# mc200 register map
Registers are 32-bit, access not given, no defined reset value unless marked. A register's access mark holds for its fields unless they carry their own. Addresses are absolute; registers are grouped by the start of their names; [hi:lo] are bit positions; {n}, {i} and the like mark numbered series.

## PMU
0x480A0000 PMU_PWR_MODE
  [1:0] PWR_MODE
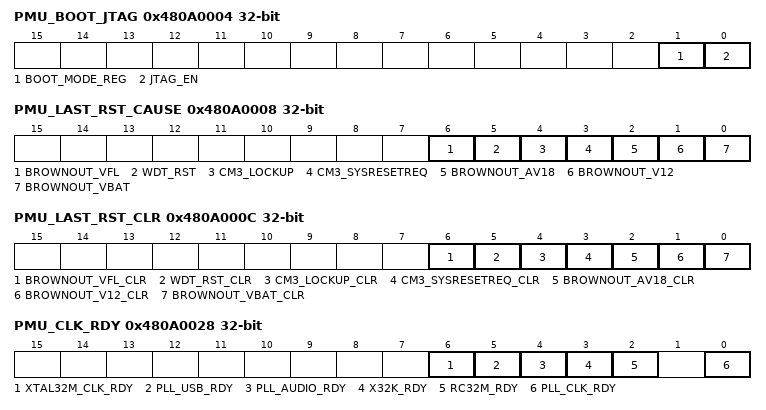
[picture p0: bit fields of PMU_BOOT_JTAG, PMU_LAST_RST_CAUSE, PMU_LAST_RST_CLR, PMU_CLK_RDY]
0x480A0004 PMU_BOOT_JTAG
  [1] BOOT_MODE_REG, [0] JTAG_EN
0x480A0008 PMU_LAST_RST_CAUSE
  [6] BROWNOUT_VFL, [5] WDT_RST, [4] CM3_LOCKUP, [3] CM3_SYSRESETREQ, [2] BROWNOUT_AV18, [1] BROWNOUT_V12, [0] BROWNOUT_VBAT
0x480A000C PMU_LAST_RST_CLR
  [6] BROWNOUT_VFL_CLR, [5] WDT_RST_CLR, [4] CM3_LOCKUP_CLR, [3] CM3_SYSRESETREQ_CLR, [2] BROWNOUT_AV18_CLR, [1] BROWNOUT_V12_CLR, [0] BROWNOUT_VBAT_CLR
0x480A0010 PMU_WAKE_SRC_CLR
  [0] CLR_PIN_INT
0x480A0018 PMU_CLK_SRC
  [1:0] SYS_CLK_SEL
0x480A0020 PMU_CLK_DIV
  [5:0] DIV_RATIO
0x480A0024 PMU_VFL_CTRL
  [0] VFL_CTRL
0x480A0028 PMU_CLK_RDY
  [6] XTAL32M_CLK_RDY, [5] PLL_USB_RDY, [4] PLL_AUDIO_RDY, [3] X32K_RDY, [2] RC32M_RDY, [0] PLL_CLK_RDY
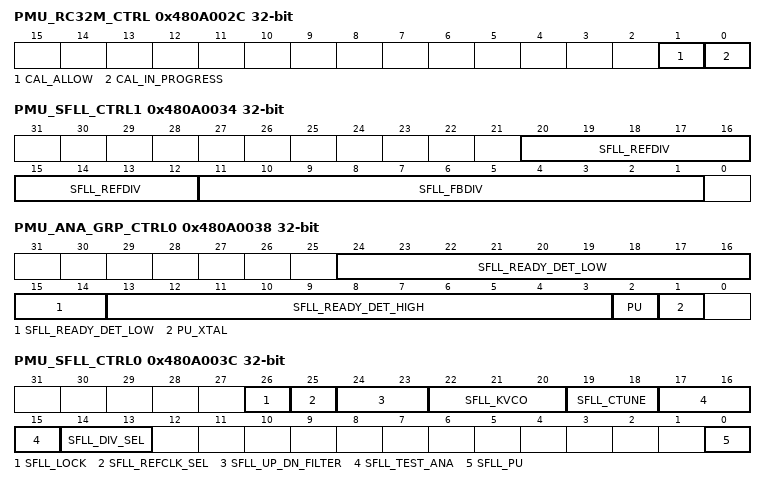
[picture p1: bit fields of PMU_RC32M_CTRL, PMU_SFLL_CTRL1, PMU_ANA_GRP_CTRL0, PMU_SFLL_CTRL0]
0x480A002C PMU_RC32M_CTRL
  [1] CAL_ALLOW, [0] CAL_IN_PROGRESS
0x480A0034 PMU_SFLL_CTRL1
  [20:12] SFLL_REFDIV, [11:1] SFLL_FBDIV
0x480A0038 PMU_ANA_GRP_CTRL0
  [24:14] SFLL_READY_DET_LOW, [13:3] SFLL_READY_DET_HIGH, [2] PU, [1] PU_XTAL
0x480A003C PMU_SFLL_CTRL0
  [26] SFLL_LOCK, [25] SFLL_REFCLK_SEL, [24:23] SFLL_UP_DN_FILTER, [22:20] SFLL_KVCO, [19:18] SFLL_CTUNE, [17:15] SFLL_TEST_ANA, [14:13] SFLL_DIV_SEL, [0] SFLL_PU
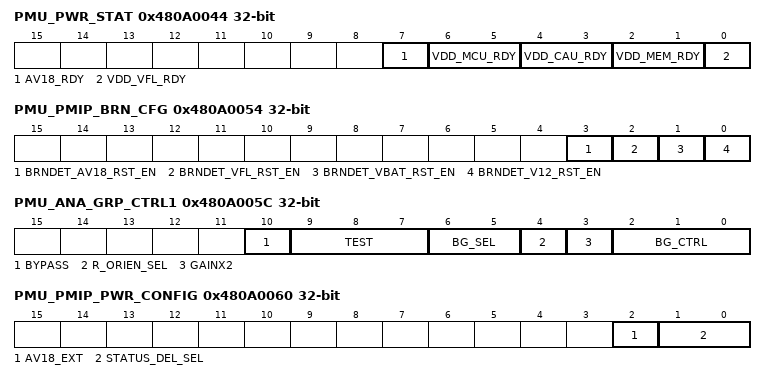
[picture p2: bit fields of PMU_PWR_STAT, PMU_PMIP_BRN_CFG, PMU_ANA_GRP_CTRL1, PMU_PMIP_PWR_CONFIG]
0x480A0044 PMU_PWR_STAT
  [7] AV18_RDY, [6:5] VDD_MCU_RDY, [4:3] VDD_CAU_RDY, [2:1] VDD_MEM_RDY, [0] VDD_VFL_RDY
0x480A0054 PMU_PMIP_BRN_CFG
  [3] BRNDET_AV18_RST_EN, [2] BRNDET_VFL_RST_EN, [1] BRNDET_VBAT_RST_EN, [0] BRNDET_V12_RST_EN
0x480A005C PMU_ANA_GRP_CTRL1
  [10] BYPASS, [9:7] TEST, [6:5] BG_SEL, [4] R_ORIEN_SEL, [3] GAINX2, [2:0] BG_CTRL
0x480A0060 PMU_PMIP_PWR_CONFIG
  [2] AV18_EXT, [1:0] STATUS_DEL_SEL
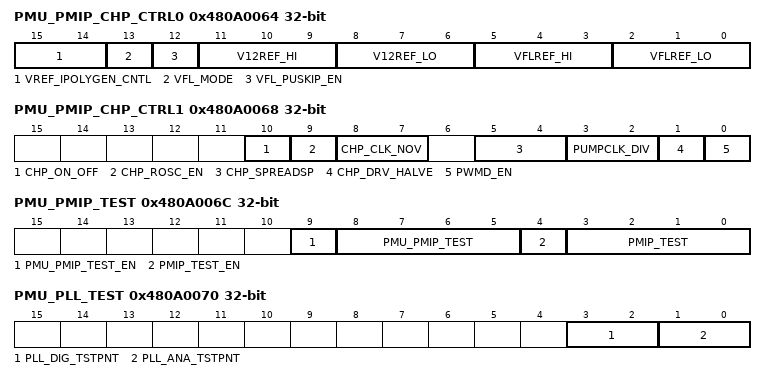
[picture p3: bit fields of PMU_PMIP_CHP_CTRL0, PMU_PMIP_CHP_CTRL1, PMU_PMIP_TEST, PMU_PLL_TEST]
0x480A0064 PMU_PMIP_CHP_CTRL0
  [15:14] VREF_IPOLYGEN_CNTL, [13] VFL_MODE, [12] VFL_PUSKIP_EN, [11:9] V12REF_HI, [8:6] V12REF_LO, [5:3] VFLREF_HI, [2:0] VFLREF_LO
0x480A0068 PMU_PMIP_CHP_CTRL1
  [10] CHP_ON_OFF, [9] CHP_ROSC_EN, [8:7] CHP_CLK_NOV, [5:4] CHP_SPREADSP, [3:2] PUMPCLK_DIV, [1] CHP_DRV_HALVE, [0] PWMD_EN
0x480A006C PMU_PMIP_TEST
  [9] PMU_PMIP_TEST_EN, [8:5] PMU_PMIP_TEST, [4] PMIP_TEST_EN, [3:0] PMIP_TEST
0x480A0070 PMU_PLL_TEST
  [3:2] PLL_DIG_TSTPNT, [1:0] PLL_ANA_TSTPNT
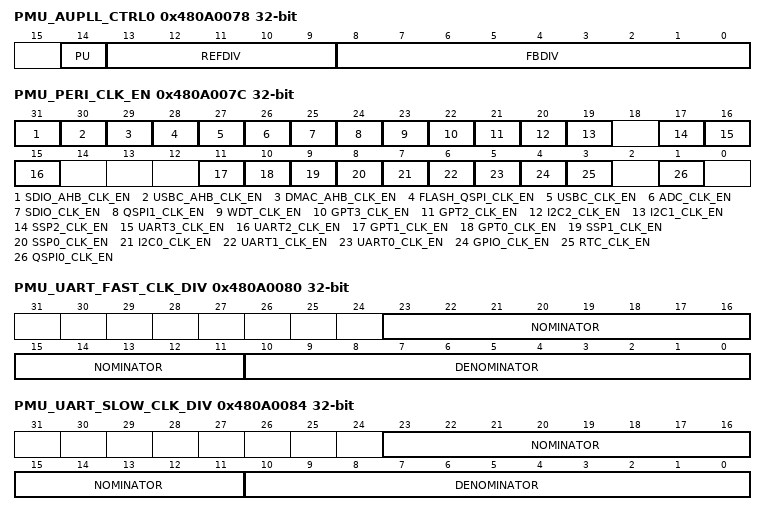
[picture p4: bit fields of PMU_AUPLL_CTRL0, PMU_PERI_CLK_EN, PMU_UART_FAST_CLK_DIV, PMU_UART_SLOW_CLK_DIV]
0x480A0078 PMU_AUPLL_CTRL0
  [14] PU, [13:9] REFDIV, [8:0] FBDIV
0x480A007C PMU_PERI_CLK_EN
  [31] SDIO_AHB_CLK_EN, [30] USBC_AHB_CLK_EN, [29] DMAC_AHB_CLK_EN, [28] FLASH_QSPI_CLK_EN, [27] USBC_CLK_EN, [26] ADC_CLK_EN, [25] SDIO_CLK_EN, [24] QSPI1_CLK_EN, [23] WDT_CLK_EN, [22] GPT3_CLK_EN, [21] GPT2_CLK_EN, [20] I2C2_CLK_EN, [19] I2C1_CLK_EN, [17] SSP2_CLK_EN, [16] UART3_CLK_EN, [15] UART2_CLK_EN, [11] GPT1_CLK_EN, [10] GPT0_CLK_EN, [9] SSP1_CLK_EN, [8] SSP0_CLK_EN, [7] I2C0_CLK_EN, [6] UART1_CLK_EN, [5] UART0_CLK_EN, [4] GPIO_CLK_EN, [3] RTC_CLK_EN, [1] QSPI0_CLK_EN
0x480A0080 PMU_UART_FAST_CLK_DIV
  [23:11] NOMINATOR, [10:0] DENOMINATOR
0x480A0084 PMU_UART_SLOW_CLK_DIV
  [23:11] NOMINATOR, [10:0] DENOMINATOR
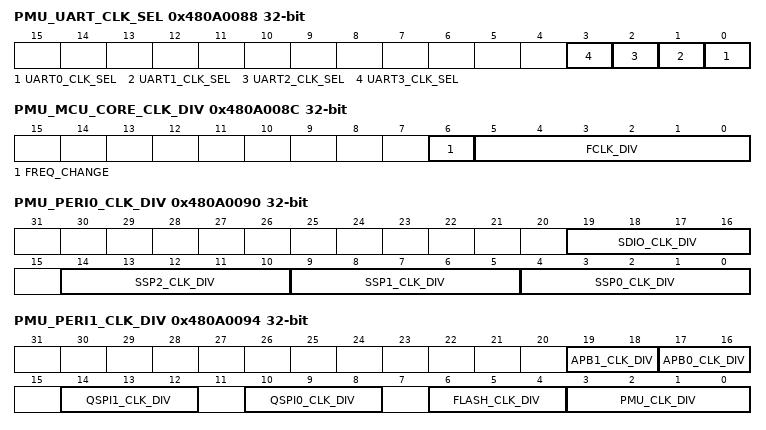
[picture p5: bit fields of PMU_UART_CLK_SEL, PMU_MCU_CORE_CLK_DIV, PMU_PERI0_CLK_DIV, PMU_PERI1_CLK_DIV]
0x480A0088 PMU_UART_CLK_SEL
  [n] UART{n}_CLK_SEL (n=0..3)
0x480A008C PMU_MCU_CORE_CLK_DIV
  [6] FREQ_CHANGE, [5:0] FCLK_DIV
0x480A0090 PMU_PERI0_CLK_DIV
  [19:16] SDIO_CLK_DIV, [14:10] SSP2_CLK_DIV, [9:5] SSP1_CLK_DIV, [4:0] SSP0_CLK_DIV
0x480A0094 PMU_PERI1_CLK_DIV
  [19:18] APB1_CLK_DIV, [17:16] APB0_CLK_DIV, [14:12] QSPI1_CLK_DIV, [10:8] QSPI0_CLK_DIV, [6:4] FLASH_CLK_DIV, [3:0] PMU_CLK_DIV
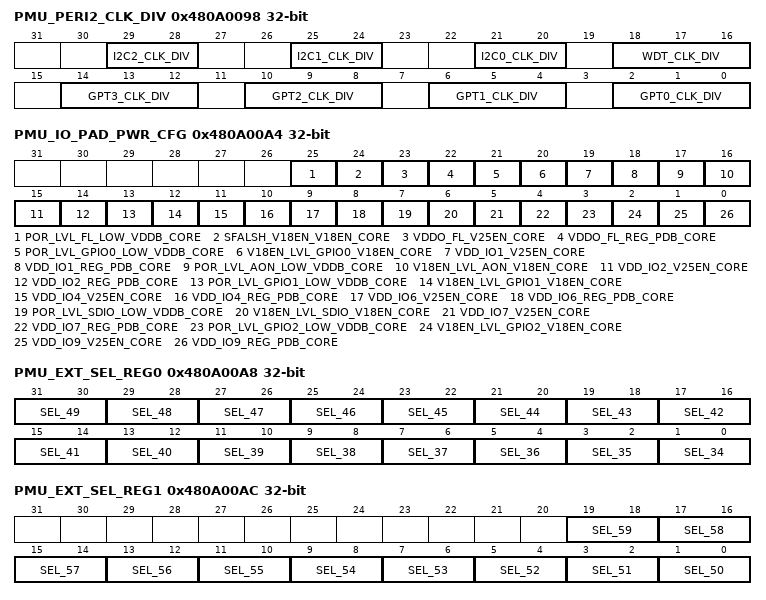
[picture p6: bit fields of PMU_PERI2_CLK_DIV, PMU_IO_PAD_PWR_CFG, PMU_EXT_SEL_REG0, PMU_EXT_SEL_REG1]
0x480A0098 PMU_PERI2_CLK_DIV
  [29:28] I2C2_CLK_DIV, [25:24] I2C1_CLK_DIV, [21:20] I2C0_CLK_DIV, [18:16] WDT_CLK_DIV, [4n+2:4n] GPT{n}_CLK_DIV (n=0..3)
0x480A009C PMU_CAU_CLK_SEL
  [1:0] CAU_CLK_SEL
0x480A00A4 PMU_IO_PAD_PWR_CFG
  [25] POR_LVL_FL_LOW_VDDB_CORE, [24] SFALSH_V18EN_V18EN_CORE, [23] VDDO_FL_V25EN_CORE, [22] VDDO_FL_REG_PDB_CORE, [21] POR_LVL_GPIO0_LOW_VDDB_CORE, [20] V18EN_LVL_GPIO0_V18EN_CORE, [19] VDD_IO1_V25EN_CORE, [18] VDD_IO1_REG_PDB_CORE, [17] POR_LVL_AON_LOW_VDDB_CORE, [16] V18EN_LVL_AON_V18EN_CORE, [15] VDD_IO2_V25EN_CORE, [14] VDD_IO2_REG_PDB_CORE, [13] POR_LVL_GPIO1_LOW_VDDB_CORE, [12] V18EN_LVL_GPIO1_V18EN_CORE, [11] VDD_IO4_V25EN_CORE, [10] VDD_IO4_REG_PDB_CORE, [9] VDD_IO6_V25EN_CORE, [8] VDD_IO6_REG_PDB_CORE, [7] POR_LVL_SDIO_LOW_VDDB_CORE, [6] V18EN_LVL_SDIO_V18EN_CORE, [5] VDD_IO7_V25EN_CORE, [4] VDD_IO7_REG_PDB_CORE, [3] POR_LVL_GPIO2_LOW_VDDB_CORE, [2] V18EN_LVL_GPIO2_V18EN_CORE, [1] VDD_IO9_V25EN_CORE, [0] VDD_IO9_REG_PDB_CORE
0x480A00A8 PMU_EXT_SEL_REG0
  [2n-67:2n-68] SEL_{n} (n=34..49)
0x480A00AC PMU_EXT_SEL_REG1
  [2n-99:2n-100] SEL_{n} (n=50..59)
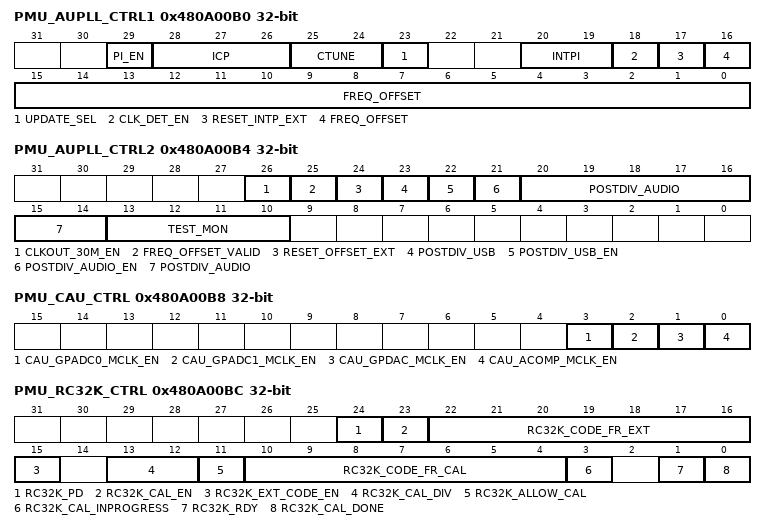
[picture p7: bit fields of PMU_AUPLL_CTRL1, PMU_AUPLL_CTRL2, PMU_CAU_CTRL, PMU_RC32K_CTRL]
0x480A00B0 PMU_AUPLL_CTRL1
  [29] PI_EN, [28:26] ICP, [25:24] CTUNE, [23] UPDATE_SEL, [20:19] INTPI, [18] CLK_DET_EN, [17] RESET_INTP_EXT, [16:0] FREQ_OFFSET
0x480A00B4 PMU_AUPLL_CTRL2
  [26] CLKOUT_30M_EN, [25] FREQ_OFFSET_VALID, [24] RESET_OFFSET_EXT, [23] POSTDIV_USB, [22] POSTDIV_USB_EN, [21] POSTDIV_AUDIO_EN, [20:14] POSTDIV_AUDIO, [13:10] TEST_MON
0x480A00B8 PMU_CAU_CTRL
  [3] CAU_GPADC0_MCLK_EN, [2] CAU_GPADC1_MCLK_EN, [1] CAU_GPDAC_MCLK_EN, [0] CAU_ACOMP_MCLK_EN
0x480A00BC PMU_RC32K_CTRL
  [24] RC32K_PD, [23] RC32K_CAL_EN, [22:16] RC32K_CODE_FR_EXT, [15] RC32K_EXT_CODE_EN, [13:12] RC32K_CAL_DIV, [11] RC32K_ALLOW_CAL, [10:4] RC32K_CODE_FR_CAL, [3] RC32K_CAL_INPROGRESS, [1] RC32K_RDY, [0] RC32K_CAL_DONE
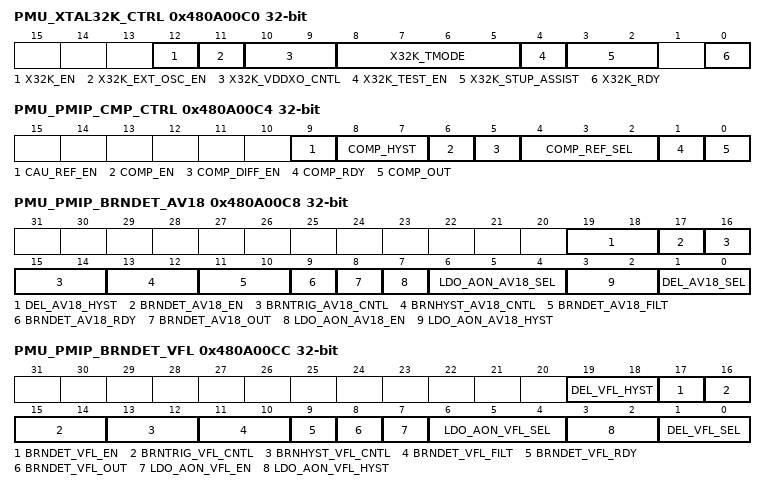
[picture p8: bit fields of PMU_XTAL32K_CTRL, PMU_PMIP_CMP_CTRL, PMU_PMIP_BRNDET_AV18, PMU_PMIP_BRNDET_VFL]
0x480A00C0 PMU_XTAL32K_CTRL
  [12] X32K_EN, [11] X32K_EXT_OSC_EN, [10:9] X32K_VDDXO_CNTL, [8:5] X32K_TMODE, [4] X32K_TEST_EN, [3:2] X32K_STUP_ASSIST, [0] X32K_RDY
0x480A00C4 PMU_PMIP_CMP_CTRL
  [9] CAU_REF_EN, [8:7] COMP_HYST, [6] COMP_EN, [5] COMP_DIFF_EN, [4:2] COMP_REF_SEL, [1] COMP_RDY, [0] COMP_OUT
0x480A00C8 PMU_PMIP_BRNDET_AV18
  [19:18] DEL_AV18_HYST, [17] BRNDET_AV18_EN, [16:14] BRNTRIG_AV18_CNTL, [13:12] BRNHYST_AV18_CNTL, [11:10] BRNDET_AV18_FILT, [9] BRNDET_AV18_RDY, [8] BRNDET_AV18_OUT, [7] LDO_AON_AV18_EN, [6:4] LDO_AON_AV18_SEL, [3:2] LDO_AON_AV18_HYST, [1:0] DEL_AV18_SEL
0x480A00CC PMU_PMIP_BRNDET_VFL
  [19:18] DEL_VFL_HYST, [17] BRNDET_VFL_EN, [16:14] BRNTRIG_VFL_CNTL, [13:12] BRNHYST_VFL_CNTL, [11:10] BRNDET_VFL_FILT, [9] BRNDET_VFL_RDY, [8] BRNDET_VFL_OUT, [7] LDO_AON_VFL_EN, [6:4] LDO_AON_VFL_SEL, [3:2] LDO_AON_VFL_HYST, [1:0] DEL_VFL_SEL
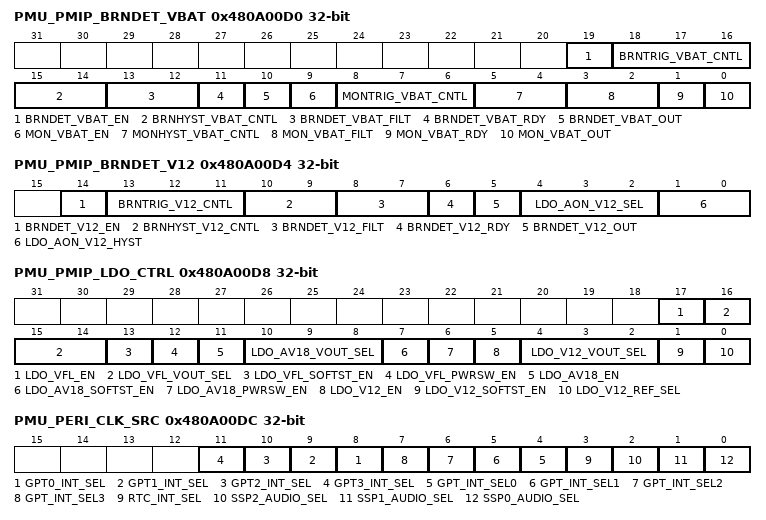
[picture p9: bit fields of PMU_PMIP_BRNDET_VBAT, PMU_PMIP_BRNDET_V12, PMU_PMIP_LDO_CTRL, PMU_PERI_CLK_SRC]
0x480A00D0 PMU_PMIP_BRNDET_VBAT
  [19] BRNDET_VBAT_EN, [18:16] BRNTRIG_VBAT_CNTL, [15:14] BRNHYST_VBAT_CNTL, [13:12] BRNDET_VBAT_FILT, [11] BRNDET_VBAT_RDY, [10] BRNDET_VBAT_OUT, [9] MON_VBAT_EN, [8:6] MONTRIG_VBAT_CNTL, [5:4] MONHYST_VBAT_CNTL, [3:2] MON_VBAT_FILT, [1] MON_VBAT_RDY, [0] MON_VBAT_OUT
0x480A00D4 PMU_PMIP_BRNDET_V12
  [14] BRNDET_V12_EN, [13:11] BRNTRIG_V12_CNTL, [10:9] BRNHYST_V12_CNTL, [8:7] BRNDET_V12_FILT, [6] BRNDET_V12_RDY, [5] BRNDET_V12_OUT, [4:2] LDO_AON_V12_SEL, [1:0] LDO_AON_V12_HYST
0x480A00D8 PMU_PMIP_LDO_CTRL
  [17] LDO_VFL_EN, [16:14] LDO_VFL_VOUT_SEL, [13] LDO_VFL_SOFTST_EN, [12] LDO_VFL_PWRSW_EN, [11] LDO_AV18_EN, [10:8] LDO_AV18_VOUT_SEL, [7] LDO_AV18_SOFTST_EN, [6] LDO_AV18_PWRSW_EN, [5] LDO_V12_EN, [4:2] LDO_V12_VOUT_SEL, [1] LDO_V12_SOFTST_EN, [0] LDO_V12_REF_SEL
0x480A00DC PMU_PERI_CLK_SRC
  [n+8] GPT{n}_INT_SEL (n=0..3), [n+4] GPT_INT_SEL{n} (n=0..3), [3] RTC_INT_SEL, [2] SSP2_AUDIO_SEL, [1] SSP1_AUDIO_SEL, [0] SSP0_AUDIO_SEL
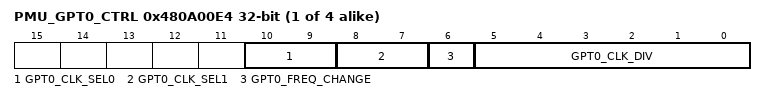
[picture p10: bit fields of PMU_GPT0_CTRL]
{0x480A00E4+4i} PMU_GPT{i}_CTRL (i=0..3)
  [10:9] GPT{i}_CLK_SEL0, [8:7] GPT{i}_CLK_SEL1, [6] GPT{i}_FREQ_CHANGE, [5:0] GPT{i}_CLK_DIV
